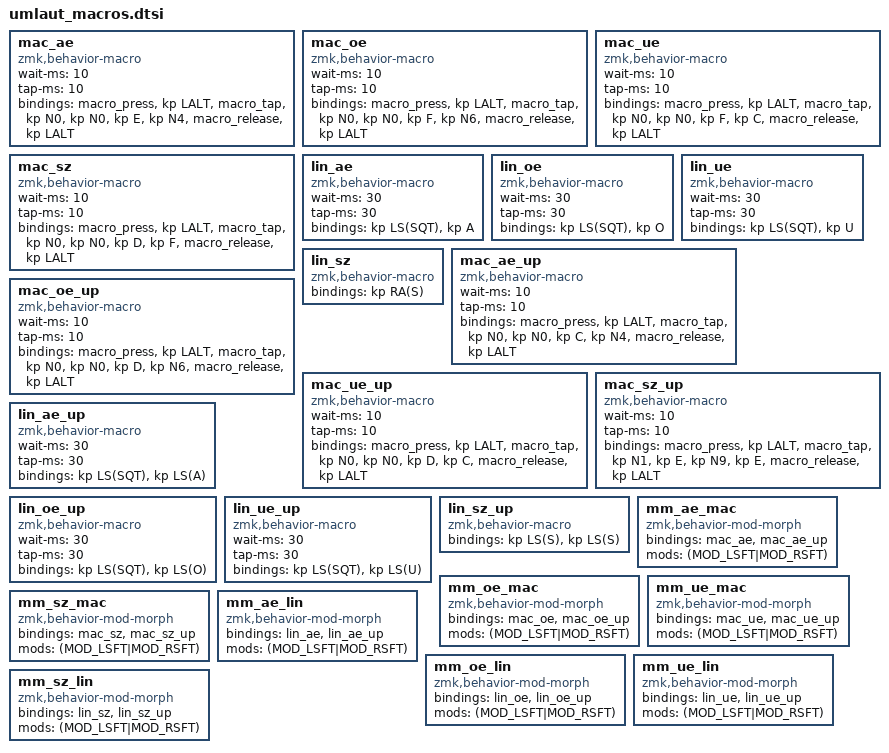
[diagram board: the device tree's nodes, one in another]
mac_ae: mac_ae {
    compatible = "zmk,behavior-macro";
    #binding-cells = <0>;
    wait-ms = <10>;
    tap-ms = <10>;
    bindings
        = <&macro_press &kp LALT>
        , <&macro_tap>
        , <&kp N0>, <&kp N0>, <&kp E>, <&kp N4>
        , <&macro_release &kp LALT>
        ;
};
mac_oe: mac_oe {
    compatible = "zmk,behavior-macro";
    #binding-cells = <0>;
    wait-ms = <10>;
    tap-ms = <10>;
    bindings
        = <&macro_press &kp LALT>
        , <&macro_tap>
        , <&kp N0>, <&kp N0>, <&kp F>, <&kp N6>
        , <&macro_release &kp LALT>
        ;
};
mac_ue: mac_ue {
    compatible = "zmk,behavior-macro";
    #binding-cells = <0>;
    wait-ms = <10>;
    tap-ms = <10>;
    bindings
        = <&macro_press &kp LALT>
        , <&macro_tap>
        , <&kp N0>, <&kp N0>, <&kp F>, <&kp C>
        , <&macro_release &kp LALT>
        ;
};
mac_sz: mac_sz {
    compatible = "zmk,behavior-macro";
    #binding-cells = <0>;
    wait-ms = <10>;
    tap-ms = <10>;
    bindings
        = <&macro_press &kp LALT>
        , <&macro_tap>
        , <&kp N0>, <&kp N0>, <&kp D>, <&kp F>
        , <&macro_release &kp LALT>
        ;
};
lin_ae: lin_ae {
    compatible = "zmk,behavior-macro";
    #binding-cells = <0>;
    wait-ms = <30>;
    tap-ms = <30>;
    bindings = <&kp LS(SQT)>, <&kp A>;
};
lin_oe: lin_oe {
    compatible = "zmk,behavior-macro";
    #binding-cells = <0>;
    wait-ms = <30>;
    tap-ms = <30>;
    bindings = <&kp LS(SQT)>, <&kp O>;
};
lin_ue: lin_ue {
    compatible = "zmk,behavior-macro";
    #binding-cells = <0>;
    wait-ms = <30>;
    tap-ms = <30>;
    bindings = <&kp LS(SQT)>, <&kp U>;
};
lin_sz: lin_sz {
    compatible = "zmk,behavior-macro";
    #binding-cells = <0>;
    bindings = <&kp RA(S)>;
};
mac_ae_up: mac_ae_up {
    compatible = "zmk,behavior-macro";
    #binding-cells = <0>;
    wait-ms = <10>;
    tap-ms = <10>;
    bindings
        = <&macro_press &kp LALT>
        , <&macro_tap>
        , <&kp N0>, <&kp N0>, <&kp C>, <&kp N4>
        , <&macro_release &kp LALT>
        ;
};
mac_oe_up: mac_oe_up {
    compatible = "zmk,behavior-macro";
    #binding-cells = <0>;
    wait-ms = <10>;
    tap-ms = <10>;
    bindings
        = <&macro_press &kp LALT>
        , <&macro_tap>
        , <&kp N0>, <&kp N0>, <&kp D>, <&kp N6>
        , <&macro_release &kp LALT>
        ;
};
mac_ue_up: mac_ue_up {
    compatible = "zmk,behavior-macro";
    #binding-cells = <0>;
    wait-ms = <10>;
    tap-ms = <10>;
    bindings
        = <&macro_press &kp LALT>
        , <&macro_tap>
        , <&kp N0>, <&kp N0>, <&kp D>, <&kp C>
        , <&macro_release &kp LALT>
        ;
};
mac_sz_up: mac_sz_up {
    compatible = "zmk,behavior-macro";
    #binding-cells = <0>;
    wait-ms = <10>;
    tap-ms = <10>;
    bindings
        = <&macro_press &kp LALT>
        , <&macro_tap>
        , <&kp N1>, <&kp E>, <&kp N9>, <&kp E>
        , <&macro_release &kp LALT>
        ;
};
lin_ae_up: lin_ae_up {
    compatible = "zmk,behavior-macro";
    #binding-cells = <0>;
    wait-ms = <30>;
    tap-ms = <30>;
    bindings = <&kp LS(SQT)>, <&kp LS(A)>;
};
lin_oe_up: lin_oe_up {
    compatible = "zmk,behavior-macro";
    #binding-cells = <0>;
    wait-ms = <30>;
    tap-ms = <30>;
    bindings = <&kp LS(SQT)>, <&kp LS(O)>;
};
lin_ue_up: lin_ue_up {
    compatible = "zmk,behavior-macro";
    #binding-cells = <0>;
    wait-ms = <30>;
    tap-ms = <30>;
    bindings = <&kp LS(SQT)>, <&kp LS(U)>;
};
lin_sz_up: lin_sz_up {
    compatible = "zmk,behavior-macro";
    #binding-cells = <0>;
    bindings = <&kp LS(S)>, <&kp LS(S)>;
};
mm_ae_mac: mm_ae_mac {
    compatible = "zmk,behavior-mod-morph";
    #binding-cells = <0>;
    bindings = <&mac_ae>, <&mac_ae_up>;
    mods = <(MOD_LSFT|MOD_RSFT)>;
};
mm_oe_mac: mm_oe_mac {
    compatible = "zmk,behavior-mod-morph";
    #binding-cells = <0>;
    bindings = <&mac_oe>, <&mac_oe_up>;
    mods = <(MOD_LSFT|MOD_RSFT)>;
};
mm_ue_mac: mm_ue_mac {
    compatible = "zmk,behavior-mod-morph";
    #binding-cells = <0>;
    bindings = <&mac_ue>, <&mac_ue_up>;
    mods = <(MOD_LSFT|MOD_RSFT)>;
};
mm_sz_mac: mm_sz_mac {
    compatible = "zmk,behavior-mod-morph";
    #binding-cells = <0>;
    bindings = <&mac_sz>, <&mac_sz_up>;
    mods = <(MOD_LSFT|MOD_RSFT)>;
};
mm_ae_lin: mm_ae_lin {
    compatible = "zmk,behavior-mod-morph";
    #binding-cells = <0>;
    bindings = <&lin_ae>, <&lin_ae_up>;
    mods = <(MOD_LSFT|MOD_RSFT)>;
};
mm_oe_lin: mm_oe_lin {
    compatible = "zmk,behavior-mod-morph";
    #binding-cells = <0>;
    bindings = <&lin_oe>, <&lin_oe_up>;
    mods = <(MOD_LSFT|MOD_RSFT)>;
};
mm_ue_lin: mm_ue_lin {
    compatible = "zmk,behavior-mod-morph";
    #binding-cells = <0>;
    bindings = <&lin_ue>, <&lin_ue_up>;
    mods = <(MOD_LSFT|MOD_RSFT)>;
};
mm_sz_lin: mm_sz_lin {
    compatible = "zmk,behavior-mod-morph";
    #binding-cells = <0>;
    bindings = <&lin_sz>, <&lin_sz_up>;
    mods = <(MOD_LSFT|MOD_RSFT)>;
};
